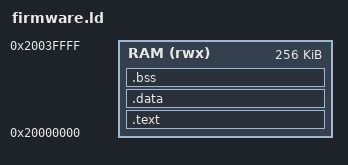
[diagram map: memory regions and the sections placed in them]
/* Bare Cortex-M0+ image: everything in SRAM, entry at _start. */
ENTRY(_start)
MEMORY { RAM (rwx) : ORIGIN = 0x20000000, LENGTH = 256K }
SECTIONS {
  .text : { KEEP(*(.text._start)) *(.text*) *(.rodata*) } > RAM
  .data : { *(.data*) } > RAM
  .bss (NOLOAD) : { *(.bss*) *(COMMON) } > RAM
  _stack_top = ORIGIN(RAM) + LENGTH(RAM);
}
